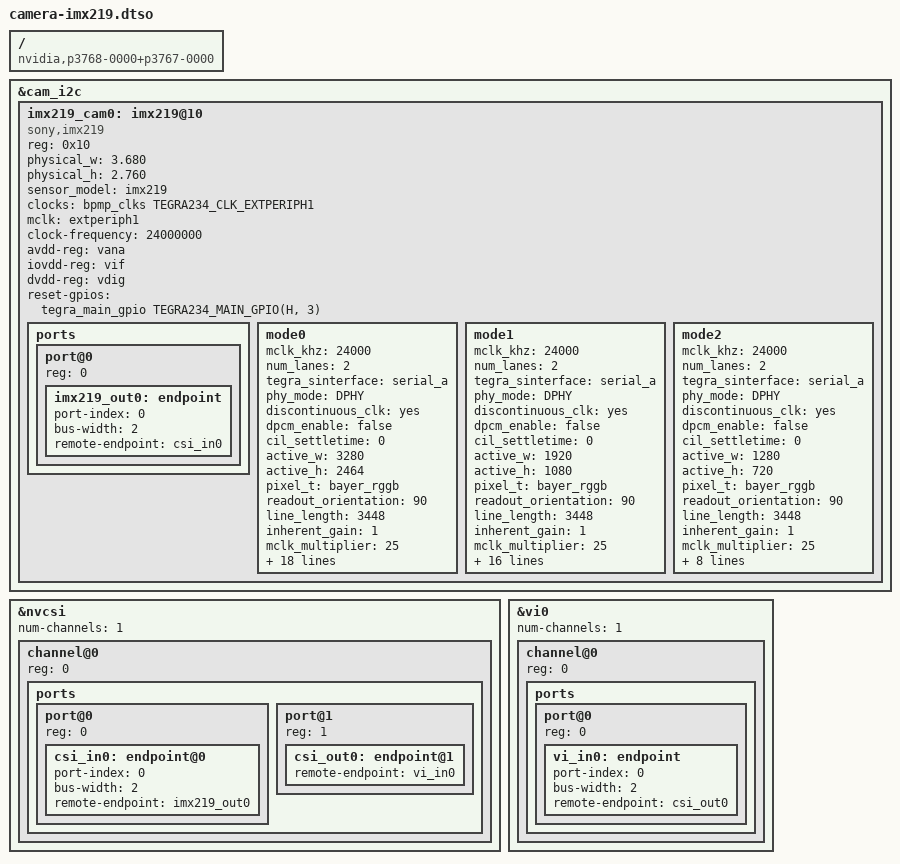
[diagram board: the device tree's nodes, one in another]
// SPDX-License-Identifier: GPL-2.0
/*
 * Device Tree Overlay: Sony IMX219 Camera Sensor
 *
 * Description: Configure IMX219 8MP camera sensor with MIPI CSI-2 interface
 *              Commonly used in Raspberry Pi Camera Module V2
 * Target: NVIDIA Jetson Orin (tegra234)
 *
 * Usage:
 *   1. Compile: dtc -@ -I dts -O dtb -o camera-imx219.dtbo camera-imx219.dtso
 *   2. Apply: Add to /boot/extlinux/extlinux.conf
 *
 * Hardware Requirements:
 *   - Sony IMX219 camera module
 *   - MIPI CSI-2 connector (15-pin FFC cable)
 *   - I2C connection for sensor control
 *
 * Connections:
 *   - MIPI CSI-2 data lanes to Jetson CSI port
 *   - I2C (CAM_I2C) for sensor configuration
 *   - MCLK from Jetson to sensor
 *   - Power: 2.8V, 1.8V, 1.2V rails
 *
 * After loading:
 *   - V4L2 device at /dev/video0
 *   - Supports multiple resolutions and framerates
 *   - GStreamer/V4L2 capture support
 */

/dts-v1/;
/plugin/;

#include <dt-bindings/clock/tegra234-clock.h>
#include <dt-bindings/gpio/tegra234-gpio.h>

/ {
    compatible = "nvidia,p3768-0000+p3767-0000", "nvidia,tegra234";

    /* Fragment 0: Enable camera I2C bus */
    fragment@0 {
        target = <&cam_i2c>;
        __overlay__ {
            status = "okay";
            #address-cells = <1>;
            #size-cells = <0>;

            /*
             * IMX219 camera sensor on I2C
             * Default address: 0x10
             */
            imx219_cam0: imx219@10 {
                compatible = "sony,imx219";
                reg = <0x10>;

                /* Physical dimensions of sensor */
                physical_w = "3.680";
                physical_h = "2.760";

                /* Sensor identification */
                sensor_model = "imx219";

                /*
                 * Clock configuration
                 * External clock (MCLK): 24 MHz
                 */
                clocks = <&bpmp_clks TEGRA234_CLK_EXTPERIPH1>;
                clock-names = "extperiph1";
                mclk = "extperiph1";
                clock-frequency = <24000000>;

                /*
                 * Power supplies
                 * VANA: Analog voltage (2.8V)
                 * VDIG: Digital core (1.2V)
                 * VDDL: Digital I/O (1.8V)
                 */
                avdd-reg = "vana";  /* 2.8V analog */
                iovdd-reg = "vif";   /* 1.8V I/O */
                dvdd-reg = "vdig";   /* 1.2V digital */

                /*
                 * Reset and enable GPIOs
                 * Adjust GPIO numbers for your board
                 */
                reset-gpios = <&tegra_main_gpio TEGRA234_MAIN_GPIO(H, 3) 0>;
                /* pwdn-gpios = <&tegra_main_gpio TEGRA234_MAIN_GPIO(H, 2) 0>; */

                /*
                 * MIPI CSI-2 port configuration
                 */
                ports {
                    #address-cells = <1>;
                    #size-cells = <0>;

                    port@0 {
                        reg = <0>;
                        imx219_out0: endpoint {
                            port-index = <0>;  /* CSI port 0 */
                            bus-width = <2>;   /* 2 data lanes */
                            remote-endpoint = <&csi_in0>;
                        };
                    };
                };

                /*
                 * Supported video modes
                 * IMX219 supports various resolutions and framerates
                 */
                mode0 {
                    /* 3280x2464 @ 21fps (Full resolution) */
                    mclk_khz = "24000";
                    num_lanes = "2";
                    tegra_sinterface = "serial_a";
                    phy_mode = "DPHY";
                    discontinuous_clk = "yes";
                    dpcm_enable = "false";
                    cil_settletime = "0";

                    active_w = "3280";
                    active_h = "2464";
                    pixel_t = "bayer_rggb";
                    readout_orientation = "90";
                    line_length = "3448";
                    inherent_gain = "1";
                    mclk_multiplier = "25";
                    pix_clk_hz = "182400000";

                    gain_factor = "16";
                    framerate_factor = "1000000";
                    exposure_factor = "1000000";
                    min_gain_val = "16";
                    max_gain_val = "256";
                    step_gain_val = "1";
                    default_gain = "16";
                    min_hdr_ratio = "1";
                    max_hdr_ratio = "1";
                    min_framerate = "2000000";
                    max_framerate = "21000000";
                    step_framerate = "1";
                    default_framerate = "21000000";
                    min_exp_time = "13";
                    max_exp_time = "683709";
                    step_exp_time = "1";
                    default_exp_time = "2495";
                };

                mode1 {
                    /* 1920x1080 @ 30fps (1080p) */
                    mclk_khz = "24000";
                    num_lanes = "2";
                    tegra_sinterface = "serial_a";
                    phy_mode = "DPHY";
                    discontinuous_clk = "yes";
                    dpcm_enable = "false";
                    cil_settletime = "0";

                    active_w = "1920";
                    active_h = "1080";
                    pixel_t = "bayer_rggb";
                    readout_orientation = "90";
                    line_length = "3448";
                    inherent_gain = "1";
                    mclk_multiplier = "25";
                    pix_clk_hz = "182400000";

                    gain_factor = "16";
                    framerate_factor = "1000000";
                    exposure_factor = "1000000";
                    min_gain_val = "16";
                    max_gain_val = "256";
                    step_gain_val = "1";
                    default_gain = "16";
                    min_framerate = "2000000";
                    max_framerate = "30000000";
                    step_framerate = "1";
                    default_framerate = "30000000";
                    min_exp_time = "13";
                    max_exp_time = "683709";
                    step_exp_time = "1";
                    default_exp_time = "2495";
                };

                mode2 {
                    /* 1280x720 @ 60fps (720p) */
                    mclk_khz = "24000";
                    num_lanes = "2";
                    tegra_sinterface = "serial_a";
                    phy_mode = "DPHY";
                    discontinuous_clk = "yes";
                    dpcm_enable = "false";
                    cil_settletime = "0";

                    active_w = "1280";
                    active_h = "720";
                    pixel_t = "bayer_rggb";
                    readout_orientation = "90";
                    line_length = "3448";
                    inherent_gain = "1";
                    mclk_multiplier = "25";
                    pix_clk_hz = "182400000";

                    gain_factor = "16";
                    min_framerate = "2000000";
                    max_framerate = "60000000";
                    default_framerate = "60000000";
                    min_exp_time = "13";
                    max_exp_time = "683709";
                    default_exp_time = "2495";
                };
            };
        };
    };

    /* Fragment 1: Enable NVCSI (NVIDIA CSI) */
    fragment@1 {
        target = <&nvcsi>;
        __overlay__ {
            status = "okay";
            num-channels = <1>;
            #address-cells = <1>;
            #size-cells = <0>;

            channel@0 {
                reg = <0>;
                ports {
                    #address-cells = <1>;
                    #size-cells = <0>;
                    port@0 {
                        reg = <0>;
                        csi_in0: endpoint@0 {
                            port-index = <0>;
                            bus-width = <2>;
                            remote-endpoint = <&imx219_out0>;
                        };
                    };
                    port@1 {
                        reg = <1>;
                        csi_out0: endpoint@1 {
                            remote-endpoint = <&vi_in0>;
                        };
                    };
                };
            };
        };
    };

    /* Fragment 2: Enable VI (Video Input) */
    fragment@2 {
        target = <&vi0>;
        __overlay__ {
            status = "okay";
            num-channels = <1>;
            #address-cells = <1>;
            #size-cells = <0>;

            channel@0 {
                reg = <0>;
                ports {
                    #address-cells = <1>;
                    #size-cells = <0>;
                    port@0 {
                        reg = <0>;
                        vi_in0: endpoint {
                            port-index = <0>;
                            bus-width = <2>;
                            remote-endpoint = <&csi_out0>;
                        };
                    };
                };
            };
        };
    };
};

/*
 * Camera Capture Examples:
 * =========================
 *
 * 1. List video devices:
 *    v4l2-ctl --list-devices
 *    # Should show IMX219 sensor
 *
 * 2. List supported formats:
 *    v4l2-ctl -d /dev/video0 --list-formats-ext
 *
 * 3. Capture with GStreamer (1080p@30fps):
 *    gst-launch-1.0 nvarguscamerasrc sensor-id=0 ! \
 *        'video/x-raw(memory:NVMM),width=1920,height=1080,framerate=30/1' ! \
 *        nvvidconv ! 'video/x-raw,format=I420' ! \
 *        xvimagesink
 *
 * 4. Save to file:
 *    gst-launch-1.0 nvarguscamerasrc sensor-id=0 num-buffers=300 ! \
 *        'video/x-raw(memory:NVMM),width=1920,height=1080,framerate=30/1' ! \
 *        omxh264enc ! qtmux ! filesink location=test.mp4
 *
 * 5. JPEG snapshot:
 *    gst-launch-1.0 nvarguscamerasrc sensor-id=0 num-buffers=1 ! \
 *        'video/x-raw(memory:NVMM),width=3280,height=2464' ! \
 *        nvjpegenc ! filesink location=snapshot.jpg
 *
 * 6. V4L2 capture (raw):
 *    v4l2-ctl -d /dev/video0 --set-fmt-video=width=1920,height=1080,pixelformat=RG10 \
 *             --stream-mmap --stream-count=10 --stream-to=capture.raw
 *
 * Python OpenCV Example:
 * ======================
 *
 * import cv2
 *
 * # GStreamer pipeline for IMX219
 * def gstreamer_pipeline(
 *     sensor_id=0,
 *     capture_width=1920,
 *     capture_height=1080,
 *     display_width=1920,
 *     display_height=1080,
 *     framerate=30,
 *     flip_method=0,
 * ):
 *     return (
 *         "nvarguscamerasrc sensor-id=%d ! "
 *         "video/x-raw(memory:NVMM), width=(int)%d, height=(int)%d, framerate=(fraction)%d/1 ! "
 *         "nvvidconv flip-method=%d ! "
 *         "video/x-raw, width=(int)%d, height=(int)%d, format=(string)BGRx ! "
 *         "videoconvert ! "
 *         "video/x-raw, format=(string)BGR ! appsink"
 *         % (
 *             sensor_id,
 *             capture_width,
 *             capture_height,
 *             framerate,
 *             flip_method,
 *             display_width,
 *             display_height,
 *         )
 *     )
 *
 * # Open camera
 * cap = cv2.VideoCapture(gstreamer_pipeline(), cv2.CAP_GSTREAMER)
 *
 * while True:
 *     ret, frame = cap.read()
 *     if not ret:
 *         break
 *
 *     cv2.imshow('IMX219 Camera', frame)
 *
 *     if cv2.waitKey(1) & 0xFF == ord('q'):
 *         break
 *
 * cap.release()
 * cv2.destroyAllWindows()
 *
 * Troubleshooting:
 * ================
 *
 * 1. Camera not detected:
 *    dmesg | grep -i imx219
 *    dmesg | grep -i csi
 *
 * 2. Check I2C communication:
 *    sudo i2cdetect -y -r 9  # CAM_I2C bus
 *    # Should show device at 0x10
 *
 * 3. Verify video device:
 *    ls -l /dev/video*
 *    v4l2-ctl --list-devices
 *
 * 4. Check camera module:
 *    # Test with NVIDIA tools
 *    nvgstcapture-1.0
 *
 * 5. Power issues:
 *    # Check camera power rails
 *    # Verify 2.8V, 1.8V, 1.2V present
 *
 * 6. No image / black screen:
 *    # Check MCLK output
 *    # Verify CSI lane connections
 *    # Test with lower resolution first
 */
